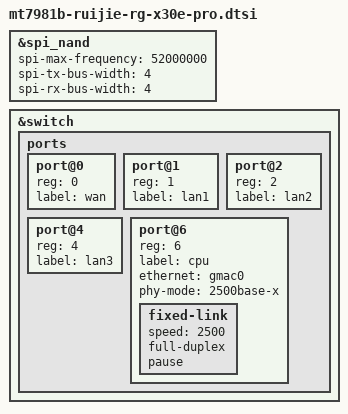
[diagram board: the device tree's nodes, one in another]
// SPDX-License-Identifier: GPL-2.0-or-later OR MIT

/dts-v1/;
#include "mt7981b-ruijie-rg-x30-base.dtsi"

&spi_nand {
	spi-max-frequency = <52000000>;

	spi-tx-bus-width = <4>;
	spi-rx-bus-width = <4>;
};

&switch {
	ports {
		#address-cells = <1>;
		#size-cells = <0>;

		port@0 {
			reg = <0>;
			label = "wan";
		};

		port@1 {
			reg = <1>;
			label = "lan1";
		};

		port@2 {
			reg = <2>;
			label = "lan2";
		};

		port@4 {
			reg = <4>;
			label = "lan3";
		};

		port@6 {
			reg = <6>;
			label = "cpu";
			ethernet = <&gmac0>;
			phy-mode = "2500base-x";

			fixed-link {
				speed = <2500>;
				full-duplex;
				pause;
			};
		};
	};
};
